AUTOSAR XML (schema 00044)
package /ComponentTypes
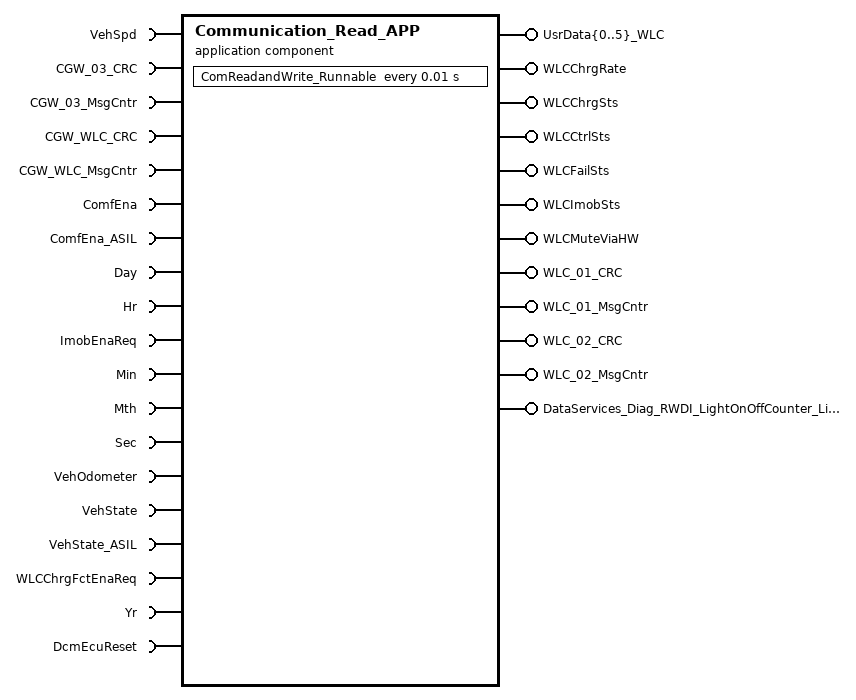
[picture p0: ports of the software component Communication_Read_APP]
  application sw component type Communication_Read_APP
    18 x require port:
      VehSpd: nonqueued-receiver-com-spec{data-element=VehSpd, filter=data-filter-type=ALWAYS, init-value=0}, required-interface=VehSpd
      CGW_03_CRC: nonqueued-receiver-com-spec{data-element=CGW_03_CRC, filter=data-filter-type=ALWAYS, init-value=0}, required-interface=CGW_03_CRC
      CGW_03_MsgCntr: nonqueued-receiver-com-spec{data-element=CGW_03_MsgCntr, filter=data-filter-type=ALWAYS, init-value=0}, required-interface=CGW_03_MsgCntr
      CGW_WLC_CRC: nonqueued-receiver-com-spec{data-element=CGW_WLC_CRC, filter=data-filter-type=ALWAYS, init-value=0}, required-interface=CGW_WLC_CRC
      CGW_WLC_MsgCntr: nonqueued-receiver-com-spec{data-element=CGW_WLC_MsgCntr, filter=data-filter-type=ALWAYS, init-value=0}, required-interface=CGW_WLC_MsgCntr
      ComfEna: nonqueued-receiver-com-spec{data-element=ComfEna, filter=data-filter-type=ALWAYS, init-value=0}, required-interface=ComfEna
      ComfEna_ASIL: nonqueued-receiver-com-spec{data-element=ComfEna_ASIL, filter=data-filter-type=ALWAYS, init-value=0}, required-interface=ComfEna_ASIL
      Day: nonqueued-receiver-com-spec{data-element=Day, filter=data-filter-type=ALWAYS, init-value=0}, required-interface=Day
      Hr: nonqueued-receiver-com-spec{data-element=Hr, filter=data-filter-type=ALWAYS, init-value=0}, required-interface=Hr
      ImobEnaReq: nonqueued-receiver-com-spec{data-element=ImobEnaReq, filter=data-filter-type=ALWAYS, init-value=0}, required-interface=ImobEnaReq
      Min: nonqueued-receiver-com-spec{data-element=Min, filter=data-filter-type=ALWAYS, init-value=0}, required-interface=Min
      Mth: nonqueued-receiver-com-spec{data-element=Mth, filter=data-filter-type=ALWAYS, init-value=0}, required-interface=Mth
      Sec: nonqueued-receiver-com-spec{data-element=Sec, filter=data-filter-type=ALWAYS, init-value=0}, required-interface=Sec
      VehOdometer: nonqueued-receiver-com-spec{data-element=VehOdometer, filter=data-filter-type=ALWAYS, init-value=0}, required-interface=VehOdometer
      VehState: nonqueued-receiver-com-spec{data-element=VehState, filter=data-filter-type=ALWAYS, init-value=0}, required-interface=VehState
      VehState_ASIL: nonqueued-receiver-com-spec{data-element=VehState_ASIL, filter=data-filter-type=ALWAYS, init-value=0}, required-interface=VehState_ASIL
      WLCChrgFctEnaReq: nonqueued-receiver-com-spec{data-element=WLCChrgFctEnaReq, filter=data-filter-type=ALWAYS, init-value=0}, required-interface=WLCChrgFctEnaReq
      Yr: nonqueued-receiver-com-spec{data-element=Yr, filter=data-filter-type=ALWAYS, init-value=0}, required-interface=Yr
    16 x provide port:
      UsrData{0..5}_WLC: nonqueued-sender-com-spec{data-element=UsrData{0..5}_WLC, init-value=0}, provided-interface=UsrData{0..5}_WLC
      WLCChrgRate: nonqueued-sender-com-spec{data-element=WLCChrgRate, init-value=0}, provided-interface=WLCChrgRate
      WLCChrgSts: nonqueued-sender-com-spec{data-element=WLCChrgSts, init-value=0}, provided-interface=WLCChrgSts
      WLCCtrlSts: nonqueued-sender-com-spec{data-element=WLCCtrlSts, init-value=0}, provided-interface=WLCCtrlSts
      WLCFailSts: nonqueued-sender-com-spec{data-element=WLCFailSts, init-value=0}, provided-interface=WLCFailSts
      WLCImobSts: nonqueued-sender-com-spec{data-element=WLCImobSts, init-value=0}, provided-interface=WLCImobSts
      WLCMuteViaHW: nonqueued-sender-com-spec{data-element=WLCMuteViaHW, init-value=0}, provided-interface=WLCMuteViaHW
      WLC_01_CRC: nonqueued-sender-com-spec{data-element=WLC_01_CRC, init-value=0}, provided-interface=WLC_01_CRC
      WLC_01_MsgCntr: nonqueued-sender-com-spec{data-element=WLC_01_MsgCntr, init-value=0}, provided-interface=WLC_01_MsgCntr
      WLC_02_CRC: nonqueued-sender-com-spec{data-element=WLC_02_CRC, init-value=0}, provided-interface=WLC_02_CRC
      WLC_02_MsgCntr: nonqueued-sender-com-spec{data-element=WLC_02_MsgCntr, init-value=0}, provided-interface=WLC_02_MsgCntr
    require port DcmEcuReset: mode-switch-receiver-com-spec=DcmEcuReset, required-interface=DcmEcuReset
    provide port DataServices_Diag_RWDI_LightOnOffCounter_LightOnOffCounter_Value: provided-interface=DataServices_Diag_RWDI_LightOnOffCounter_LightOnOffCounter_Value
      provided-com-specs:
        operation=ReadData, queue-length=1
        operation=ConditionCheckRead, queue-length=1
        operation=WriteData, queue-length=1
    behavior Communication_Read_APP_InternalBehavior
      timing event TMT_WLCAPP_Runnable: start-on-event=ComReadandWrite_Runnable, period=0.01
      operation invoked event OIT_DataServices_Diag_RWDI_LightOnOffCounter_LightOnOffCounter_Value_WriteData_DataServices_Diag_RWDI_LightOnOffCounter_9798F8A6: start-on-event=DataServices_Diag_RWDI_LightOnOffCounter_LightOnOffCounter_Value_WriteData, operation=DataServices_Diag_RWDI_LightOnOffCounter_LightOnOffCounter_Value.WriteData
      operation invoked event OIT_DataServices_Diag_RWDI_LightOnOffCounter_LightOnOffCounter_Value_ConditionCheckRead_DataServices_Diag_RWDI_LightOnOf2065F94A: start-on-event=DataServices_Diag_RWDI_LightOnOffCounter_LightOnOffCounter_Value_ConditionCheckRead, operation=DataServices_Diag_RWDI_LightOnOffCounter_LightOnOffCounter_Value.ConditionCheckRead
      operation invoked event OIT_DataServices_Diag_RWDI_LightOnOffCounter_LightOnOffCounter_Value_ReadData_DataServices_Diag_RWDI_LightOnOffCounter_LBCB6C10A: start-on-event=DataServices_Diag_RWDI_LightOnOffCounter_LightOnOffCounter_Value_ReadData, operation=DataServices_Diag_RWDI_LightOnOffCounter_LightOnOffCounter_Value.ReadData
      4 x runnable:
        ComReadandWrite_Runnable: mode-access-point=DcmEcuReset.DcmEcuReset
          data-receive-point-by-arguments:
            18 x access:
              REC_VehSpd_VehSpd: accessed-variable=VehSpd.VehSpd
              REC_CGW_03_CRC_CGW_03_CRC: accessed-variable=CGW_03_CRC.CGW_03_CRC
              REC_CGW_03_MsgCntr_CGW_03_MsgCntr: accessed-variable=CGW_03_MsgCntr.CGW_03_MsgCntr
              REC_CGW_WLC_CRC_CGW_WLC_CRC: accessed-variable=CGW_WLC_CRC.CGW_WLC_CRC
              REC_CGW_WLC_MsgCntr_CGW_WLC_MsgCntr: accessed-variable=CGW_WLC_MsgCntr.CGW_WLC_MsgCntr
              REC_ComfEna_ComfEna: accessed-variable=ComfEna.ComfEna
              REC_ComfEna_ASIL_ComfEna_ASIL: accessed-variable=ComfEna_ASIL.ComfEna_ASIL
              REC_Day_Day: accessed-variable=Day.Day
              REC_Hr_Hr: accessed-variable=Hr.Hr
              REC_ImobEnaReq_ImobEnaReq: accessed-variable=ImobEnaReq.ImobEnaReq
              REC_Min_Min: accessed-variable=Min.Min
              REC_Mth_Mth: accessed-variable=Mth.Mth
              REC_Sec_Sec: accessed-variable=Sec.Sec
              REC_VehOdometer_VehOdometer: accessed-variable=VehOdometer.VehOdometer
              REC_VehState_VehState: accessed-variable=VehState.VehState
              REC_VehState_ASIL_VehState_ASIL: accessed-variable=VehState_ASIL.VehState_ASIL
              REC_WLCChrgFctEnaReq_WLCChrgFctEnaReq: accessed-variable=WLCChrgFctEnaReq.WLCChrgFctEnaReq
              REC_Yr_Yr: accessed-variable=Yr.Yr
          data-send-points:
            16 x access:
              SEND_UsrData{0..5}_WLC_UsrData{0..5}_WLC: accessed-variable=UsrData{0..5}_WLC.UsrData{0..5}_WLC
              SEND_WLCChrgRate_WLCChrgRate: accessed-variable=WLCChrgRate.WLCChrgRate
              SEND_WLCChrgSts_WLCChrgSts: accessed-variable=WLCChrgSts.WLCChrgSts
              SEND_WLCCtrlSts_WLCCtrlSts: accessed-variable=WLCCtrlSts.WLCCtrlSts
              SEND_WLCFailSts_WLCFailSts: accessed-variable=WLCFailSts.WLCFailSts
              SEND_WLCImobSts_WLCImobSts: accessed-variable=WLCImobSts.WLCImobSts
              SEND_WLCMuteViaHW_WLCMuteViaHW: accessed-variable=WLCMuteViaHW.WLCMuteViaHW
              SEND_WLC_01_CRC_WLC_01_CRC: accessed-variable=WLC_01_CRC.WLC_01_CRC
              SEND_WLC_01_MsgCntr_WLC_01_MsgCntr: accessed-variable=WLC_01_MsgCntr.WLC_01_MsgCntr
              SEND_WLC_02_CRC_WLC_02_CRC: accessed-variable=WLC_02_CRC.WLC_02_CRC
              SEND_WLC_02_MsgCntr_WLC_02_MsgCntr: accessed-variable=WLC_02_MsgCntr.WLC_02_MsgCntr
        DataServices_Diag_RWDI_LightOnOffCounter_LightOnOffCounter_Value_WriteData
        DataServices_Diag_RWDI_LightOnOffCounter_LightOnOffCounter_Value_ConditionCheckRead
        DataServices_Diag_RWDI_LightOnOffCounter_LightOnOffCounter_Value_ReadData
  swc implementation Communication_Read_APP_Implementation: behavior=Communication_Read_APP_InternalBehavior
